VERSION "2027-draft-2026-10-23"

NS_ :

BS_:

BU_: BPS ElconInterface
VAL_TABLE_ EnableDisable 1 "Enabled" 0 "Disabled" ;
VAL_TABLE_ OnOff 1 "On" 0 "Off" ;
VAL_TABLE_ FaultState 1 "Fault" 0 "OK" ;
VAL_TABLE_ WarningState 1 "Warning" 0 "NoWarning" ;
VAL_TABLE_ DeviceStatus 2 "Waiting" 1 "Fault" 0 "OK" ;
VAL_TABLE_ Permission 1 "Allowed" 0 "NotAllowed" ;
VAL_TABLE_ Connection 1 "Connected" 0 "Disconnected" ;
VAL_TABLE_ ServerConnection 1 "Connected" 0 "Disconnected/Retrying" ;
VAL_TABLE_ Pressed 1 "Pressed" 0 "NotPressed" ;
VAL_TABLE_ Validity 1 "Valid" 0 "Invalid" ;
VAL_TABLE_ Watchdog 1 "TimedOut" 0 "Alive" ;
VAL_TABLE_ NormalAdvanced 1 "Advanced" 0 "Normal" ;
VAL_TABLE_ MotorCommandSource 1 "External" 0 "VCU" ;
VAL_TABLE_ Gear 3 "Invalid" 2 "Reverse" 1 "Forward" 0 "Neutral" ;
VAL_TABLE_ BPSFaultSummary 5 "SMBFault" 4 "PrechargeFault" 3 "ContactorRelayFault" 2 "EmergencyStop" 1 "SetpointFault" 0 "OK" ;
VAL_TABLE_ VCUState 7 "VehicleNotReady" 6 "Disabled" 5 "CruiseControl" 4 "Regen" 3 "ReverseDrive" 2 "NeutralDrive" 1 "ForwardDrive" 0 "Init" ;
VAL_TABLE_ ChargeState 2 "Charging" 1 "Standby" 0 "Disabled" ;
VAL_TABLE_ EVSEState 5 "F_EVSEFault" 4 "E_Fault" 3 "D_VentilationRequired" 2 "C_ChargingReady" 1 "B_Connected" 0 "A_Disconnected" ;
VAL_TABLE_ GPSAntennaState 3 "Unknown" 2 "ShortCircuit" 1 "OpenCircuit" 0 "OK" ;
VAL_TABLE_ GPSFix 2 "Fix3D" 1 "Fix2D" 0 "NoFix" ;
VAL_TABLE_ CellularTechnology 4 "Other" 3 "NB_IoT" 2 "LTE_M" 1 "LTE" 0 "None" ;
VAL_TABLE_ TPEEControlMode 2 "ConstantInputVoltage" 1 "PerturbAndObserve" 0 "Disabled" ;
VAL_TABLE_ TPEEOperatingMode 7 "Fault" 6 "MinimumInputVoltage" 5 "TemperatureDerating" 4 "ConstantOutputCurrent" 3 "ConstantOutputVoltage" 2 "MinimumInputCurrent" 1 "ConstantInputCurrent" 0 "ConstantInputVoltage" ;
VAL_TABLE_ TPEEFault 8 "Fault" 7 "PhaseOverCurrent" 6 "InputUnderCurrent" 5 "InputOverCurrent" 4 "OutputOverCurrent" 3 "OutputOverVoltage" 2 "InputOverVoltage" 1 "ConfigurationError" 0 "OK" ;
VAL_TABLE_ LWSCalibration 1 "Calibrated" 0 "NotCalibrated" ;
VAL_TABLE_ LWSTrim 1 "Trimmed" 0 "NotTrimmed" ;
VAL_TABLE_ LWSCommand 5 "ResetCalibration" 3 "SetAngleZero" ;
VAL_TABLE_ ElconControl 1 "Disable" 0 "Charge" ;
VAL_TABLE_ ElconMuxPage 5 "Page5" 4 "Page4" 3 "Page3" 2 "Page2" 1 "Page1" ;

BO_ 96 BPSStatus: 16 BPS
 SG_ Status : 0|2@1+ (1,0) [0.0|3.0] "" Vector__XXX
 SG_ FaultSummary : 2|3@1+ (1,0) [0.0|7.0] "" Vector__XXX
 SG_ FaultOverTemperature : 5|1@1+ (1,0) [0.0|1.0] "" Vector__XXX
 SG_ FaultOverVoltage : 6|1@1+ (1,0) [0.0|1.0] "" Vector__XXX
 SG_ FaultUnderVoltage : 7|1@1+ (1,0) [0.0|1.0] "" Vector__XXX
 SG_ FaultChargeOverCurrent : 8|1@1+ (1,0) [0.0|1.0] "" Vector__XXX
 SG_ FaultDischargeOverCurrent : 9|1@1+ (1,0) [0.0|1.0] "" Vector__XXX
 SG_ FaultHVPositiveContactorMismatch : 10|1@1+ (1,0) [0.0|1.0] "" Vector__XXX
 SG_ FaultMotorContactorMismatch : 11|1@1+ (1,0) [0.0|1.0] "" Vector__XXX
 SG_ FaultHVNegativeContactorMismatch : 12|1@1+ (1,0) [0.0|1.0] "" Vector__XXX
 SG_ FaultMainPrechargeRelayMismatch : 13|1@1+ (1,0) [0.0|1.0] "" Vector__XXX
 SG_ FaultMotorPrechargeRelayMismatch : 14|1@1+ (1,0) [0.0|1.0] "" Vector__XXX
 SG_ FaultDriverEstop : 15|1@1+ (1,0) [0.0|1.0] "" Vector__XXX
 SG_ FaultExternalEstop : 16|1@1+ (1,0) [0.0|1.0] "" Vector__XXX
 SG_ FaultBatteryEstop : 17|1@1+ (1,0) [0.0|1.0] "" Vector__XXX
 SG_ FaultChargerEstop : 18|1@1+ (1,0) [0.0|1.0] "" Vector__XXX
 SG_ FaultMainPrechargeTimeout : 19|1@1+ (1,0) [0.0|1.0] "" Vector__XXX
 SG_ FaultMotorPrechargeTimeout : 20|1@1+ (1,0) [0.0|1.0] "" Vector__XXX
 SG_ FaultMainVoltage : 21|1@1+ (1,0) [0.0|1.0] "" Vector__XXX
 SG_ FaultMotorVoltage : 22|1@1+ (1,0) [0.0|1.0] "" Vector__XXX
 SG_ FaultMainPrechargeVoltage : 23|1@1+ (1,0) [0.0|1.0] "" Vector__XXX
 SG_ FaultMotorPrechargeVoltage : 24|1@1+ (1,0) [0.0|1.0] "" Vector__XXX
 SG_ WarningSMBCommunication : 25|1@1+ (1,0) [0.0|1.0] "" Vector__XXX
 SG_ WarningUnderVoltage : 26|1@1+ (1,0) [0.0|1.0] "" Vector__XXX
 SG_ WarningOverVoltage : 27|1@1+ (1,0) [0.0|1.0] "" Vector__XXX
 SG_ WarningChargeOverTemperature : 28|1@1+ (1,0) [0.0|1.0] "" Vector__XXX
 SG_ WarningDischargeOverTemperature : 29|1@1+ (1,0) [0.0|1.0] "" Vector__XXX
 SG_ WarningBatteryFan1 : 30|1@1+ (1,0) [0.0|1.0] "" Vector__XXX
 SG_ WarningBatteryFan2 : 31|1@1+ (1,0) [0.0|1.0] "" Vector__XXX
 SG_ WarningBPSFan : 32|1@1+ (1,0) [0.0|1.0] "" Vector__XXX
 SG_ DriveOK : 33|1@1+ (1,0) [0.0|1.0] "" Vector__XXX
 SG_ ChargeOK : 34|1@1+ (1,0) [0.0|1.0] "" Vector__XXX
 SG_ MPPTSetMode : 35|2@1+ (1,0) [0.0|3.0] "" Vector__XXX
 SG_ ElconChargeOK : 37|1@1+ (1,0) [0.0|1.0] "" Vector__XXX
 SG_ RegenChargeOK : 38|1@1+ (1,0) [0.0|1.0] "" Vector__XXX
 SG_ HVPositiveContactor : 39|1@1+ (1,0) [0.0|1.0] "" Vector__XXX
 SG_ MotorContactor : 40|1@1+ (1,0) [0.0|1.0] "" Vector__XXX
 SG_ HVNegativeContactor : 41|1@1+ (1,0) [0.0|1.0] "" Vector__XXX
 SG_ MainPrechargeRelay : 42|1@1+ (1,0) [0.0|1.0] "" Vector__XXX
 SG_ MotorPrechargeRelay : 43|1@1+ (1,0) [0.0|1.0] "" Vector__XXX
 SG_ MPPTVoltageLimit : 44|16@1+ (0.05,0) [0|175] "V" Vector__XXX
 SG_ MPPTCurrentLimit : 60|16@1+ (0.01,0) [0|16.38] "A" Vector__XXX
 SG_ BatteryFanTach1 : 76|12@1+ (5,0) [0.0|20475.0] "rpm" Vector__XXX
 SG_ BatteryFanTach2 : 88|12@1+ (5,0) [0.0|20475.0] "rpm" Vector__XXX
 SG_ BPSFanTach : 100|12@1+ (5,0) [0.0|20475.0] "rpm" Vector__XXX
 SG_ SampleAgeMs : 112|16@1+ (1,0) [0|65535] "ms" Vector__XXX

BO_ 112 BPSPackData: 12 BPS
 SG_ CellSumVoltage : 0|12@1+ (0.05,0) [0.0|204.75] "V" Vector__XXX
 SG_ MainBatteryVoltage : 12|12@1+ (0.05,0) [0.0|204.75] "V" Vector__XXX
 SG_ MotorBatteryVoltage : 24|12@1+ (0.05,0) [0.0|204.75] "V" Vector__XXX
 SG_ MainVoltage : 36|12@1+ (0.05,0) [0.0|204.75] "V" Vector__XXX
 SG_ MotorVoltage : 48|12@1+ (0.05,0) [0.0|204.75] "V" Vector__XXX
 SG_ BatteryCurrent : 60|14@1+ (0.01,-50) [-50.0|113.83] "A" Vector__XXX
 SG_ SampleAgeMs : 74|16@1+ (1,0) [0|65535] "ms" Vector__XXX

BO_ 113 BPSVoltageData: 64 BPS
 SG_ CellVoltage01 : 0|12@1+ (1,2000) [2000.0|6095.0] "mV" Vector__XXX
 SG_ CellVoltage02 : 12|12@1+ (1,2000) [2000.0|6095.0] "mV" Vector__XXX
 SG_ CellVoltage03 : 24|12@1+ (1,2000) [2000.0|6095.0] "mV" Vector__XXX
 SG_ CellVoltage04 : 36|12@1+ (1,2000) [2000.0|6095.0] "mV" Vector__XXX
 SG_ CellVoltage05 : 48|12@1+ (1,2000) [2000.0|6095.0] "mV" Vector__XXX
 SG_ CellVoltage06 : 60|12@1+ (1,2000) [2000.0|6095.0] "mV" Vector__XXX
 SG_ CellVoltage07 : 72|12@1+ (1,2000) [2000.0|6095.0] "mV" Vector__XXX
 SG_ CellVoltage08 : 84|12@1+ (1,2000) [2000.0|6095.0] "mV" Vector__XXX
 SG_ CellVoltage09 : 96|12@1+ (1,2000) [2000.0|6095.0] "mV" Vector__XXX
 SG_ CellVoltage10 : 108|12@1+ (1,2000) [2000.0|6095.0] "mV" Vector__XXX
 SG_ CellVoltage11 : 120|12@1+ (1,2000) [2000.0|6095.0] "mV" Vector__XXX
 SG_ CellVoltage12 : 132|12@1+ (1,2000) [2000.0|6095.0] "mV" Vector__XXX
 SG_ CellVoltage13 : 144|12@1+ (1,2000) [2000.0|6095.0] "mV" Vector__XXX
 SG_ CellVoltage14 : 156|12@1+ (1,2000) [2000.0|6095.0] "mV" Vector__XXX
 SG_ CellVoltage15 : 168|12@1+ (1,2000) [2000.0|6095.0] "mV" Vector__XXX
 SG_ CellVoltage16 : 180|12@1+ (1,2000) [2000.0|6095.0] "mV" Vector__XXX
 SG_ CellVoltage17 : 192|12@1+ (1,2000) [2000.0|6095.0] "mV" Vector__XXX
 SG_ CellVoltage18 : 204|12@1+ (1,2000) [2000.0|6095.0] "mV" Vector__XXX
 SG_ CellVoltage19 : 216|12@1+ (1,2000) [2000.0|6095.0] "mV" Vector__XXX
 SG_ CellVoltage20 : 228|12@1+ (1,2000) [2000.0|6095.0] "mV" Vector__XXX
 SG_ CellVoltage21 : 240|12@1+ (1,2000) [2000.0|6095.0] "mV" Vector__XXX
 SG_ CellVoltage22 : 252|12@1+ (1,2000) [2000.0|6095.0] "mV" Vector__XXX
 SG_ CellVoltage23 : 264|12@1+ (1,2000) [2000.0|6095.0] "mV" Vector__XXX
 SG_ CellVoltage24 : 276|12@1+ (1,2000) [2000.0|6095.0] "mV" Vector__XXX
 SG_ CellVoltage25 : 288|12@1+ (1,2000) [2000.0|6095.0] "mV" Vector__XXX
 SG_ CellVoltage26 : 300|12@1+ (1,2000) [2000.0|6095.0] "mV" Vector__XXX
 SG_ CellVoltage27 : 312|12@1+ (1,2000) [2000.0|6095.0] "mV" Vector__XXX
 SG_ CellVoltage28 : 324|12@1+ (1,2000) [2000.0|6095.0] "mV" Vector__XXX
 SG_ CellVoltage29 : 336|12@1+ (1,2000) [2000.0|6095.0] "mV" Vector__XXX
 SG_ CellVoltage30 : 348|12@1+ (1,2000) [2000.0|6095.0] "mV" Vector__XXX
 SG_ CellVoltage31 : 360|12@1+ (1,2000) [2000.0|6095.0] "mV" Vector__XXX
 SG_ CellVoltage32 : 372|12@1+ (1,2000) [2000.0|6095.0] "mV" Vector__XXX
 SG_ MinCellVoltage : 384|12@1+ (1,2000) [2000.0|6095.0] "mV" Vector__XXX
 SG_ MaxCellVoltage : 396|12@1+ (1,2000) [2000.0|6095.0] "mV" Vector__XXX
 SG_ SampleAgeMs : 408|16@1+ (1,0) [0|65535] "ms" Vector__XXX

BO_ 114 BPSTemperatureData: 64 BPS
 SG_ CellTemperature01 : 0|11@1+ (0.05,0) [0.0|102.35] "degC" Vector__XXX
 SG_ CellTemperature02 : 11|11@1+ (0.05,0) [0.0|102.35] "degC" Vector__XXX
 SG_ CellTemperature03 : 22|11@1+ (0.05,0) [0.0|102.35] "degC" Vector__XXX
 SG_ CellTemperature04 : 33|11@1+ (0.05,0) [0.0|102.35] "degC" Vector__XXX
 SG_ CellTemperature05 : 44|11@1+ (0.05,0) [0.0|102.35] "degC" Vector__XXX
 SG_ CellTemperature06 : 55|11@1+ (0.05,0) [0.0|102.35] "degC" Vector__XXX
 SG_ CellTemperature07 : 66|11@1+ (0.05,0) [0.0|102.35] "degC" Vector__XXX
 SG_ CellTemperature08 : 77|11@1+ (0.05,0) [0.0|102.35] "degC" Vector__XXX
 SG_ CellTemperature09 : 88|11@1+ (0.05,0) [0.0|102.35] "degC" Vector__XXX
 SG_ CellTemperature10 : 99|11@1+ (0.05,0) [0.0|102.35] "degC" Vector__XXX
 SG_ CellTemperature11 : 110|11@1+ (0.05,0) [0.0|102.35] "degC" Vector__XXX
 SG_ CellTemperature12 : 121|11@1+ (0.05,0) [0.0|102.35] "degC" Vector__XXX
 SG_ CellTemperature13 : 132|11@1+ (0.05,0) [0.0|102.35] "degC" Vector__XXX
 SG_ CellTemperature14 : 143|11@1+ (0.05,0) [0.0|102.35] "degC" Vector__XXX
 SG_ CellTemperature15 : 154|11@1+ (0.05,0) [0.0|102.35] "degC" Vector__XXX
 SG_ CellTemperature16 : 165|11@1+ (0.05,0) [0.0|102.35] "degC" Vector__XXX
 SG_ CellTemperature17 : 176|11@1+ (0.05,0) [0.0|102.35] "degC" Vector__XXX
 SG_ CellTemperature18 : 187|11@1+ (0.05,0) [0.0|102.35] "degC" Vector__XXX
 SG_ CellTemperature19 : 198|11@1+ (0.05,0) [0.0|102.35] "degC" Vector__XXX
 SG_ CellTemperature20 : 209|11@1+ (0.05,0) [0.0|102.35] "degC" Vector__XXX
 SG_ CellTemperature21 : 220|11@1+ (0.05,0) [0.0|102.35] "degC" Vector__XXX
 SG_ CellTemperature22 : 231|11@1+ (0.05,0) [0.0|102.35] "degC" Vector__XXX
 SG_ CellTemperature23 : 242|11@1+ (0.05,0) [0.0|102.35] "degC" Vector__XXX
 SG_ CellTemperature24 : 253|11@1+ (0.05,0) [0.0|102.35] "degC" Vector__XXX
 SG_ CellTemperature25 : 264|11@1+ (0.05,0) [0.0|102.35] "degC" Vector__XXX
 SG_ CellTemperature26 : 275|11@1+ (0.05,0) [0.0|102.35] "degC" Vector__XXX
 SG_ CellTemperature27 : 286|11@1+ (0.05,0) [0.0|102.35] "degC" Vector__XXX
 SG_ CellTemperature28 : 297|11@1+ (0.05,0) [0.0|102.35] "degC" Vector__XXX
 SG_ CellTemperature29 : 308|11@1+ (0.05,0) [0.0|102.35] "degC" Vector__XXX
 SG_ CellTemperature30 : 319|11@1+ (0.05,0) [0.0|102.35] "degC" Vector__XXX
 SG_ CellTemperature31 : 330|11@1+ (0.05,0) [0.0|102.35] "degC" Vector__XXX
 SG_ CellTemperature32 : 341|11@1+ (0.05,0) [0.0|102.35] "degC" Vector__XXX
 SG_ MaxBatteryTemperature : 352|11@1+ (0.05,0) [0.0|102.35] "degC" Vector__XXX
 SG_ AverageBatteryTemperature : 363|11@1+ (0.05,0) [0.0|102.35] "degC" Vector__XXX
 SG_ SampleAgeMs : 374|16@1+ (1,0) [0|65535] "ms" Vector__XXX

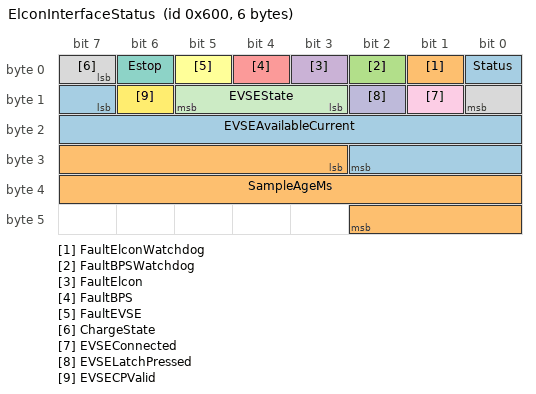
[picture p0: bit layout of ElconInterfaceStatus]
BO_ 1536 ElconInterfaceStatus: 6 ElconInterface
 SG_ Status : 0|1@1+ (1,0) [0.0|1.0] "" Vector__XXX
 SG_ FaultElconWatchdog : 1|1@1+ (1,0) [0.0|1.0] "" Vector__XXX
 SG_ FaultBPSWatchdog : 2|1@1+ (1,0) [0.0|1.0] "" Vector__XXX
 SG_ FaultElcon : 3|1@1+ (1,0) [0.0|1.0] "" Vector__XXX
 SG_ FaultBPS : 4|1@1+ (1,0) [0.0|1.0] "" Vector__XXX
 SG_ FaultEVSE : 5|1@1+ (1,0) [0.0|1.0] "" Vector__XXX
 SG_ Estop : 6|1@1+ (1,0) [0.0|1.0] "" Vector__XXX
 SG_ ChargeState : 7|2@1+ (1,0) [0.0|3.0] "" Vector__XXX
 SG_ EVSEConnected : 9|1@1+ (1,0) [0.0|1.0] "" Vector__XXX
 SG_ EVSELatchPressed : 10|1@1+ (1,0) [0.0|1.0] "" Vector__XXX
 SG_ EVSEState : 11|3@1+ (1,0) [0.0|7.0] "" Vector__XXX
 SG_ EVSECPValid : 14|1@1+ (1,0) [0.0|1.0] "" Vector__XXX
 SG_ EVSEAvailableCurrent : 15|12@1+ (0.01,0) [0|25.5] "A" Vector__XXX
 SG_ SampleAgeMs : 27|16@1+ (1,0) [0|65535] "ms" Vector__XXX

CM_ BO_ 96 "BPS faults, warnings, state, contactors, control permissions, MPPT limits, and fan tachometers. Pack measurements are in BPSPackData (0x070). CAN-FD; no transmit period assigned yet.";
CM_ SG_ 96 SampleAgeMs "Age in milliseconds of the oldest continuous sensor sample included in this frame when assembled; saturates at 65535. Age must advance for cached samples. In a fault snapshot, freeze age at fault detection; per-channel captured ages, if present, remain authoritative for individual trip records.";
CM_ SG_ 96 BPSFanTach "BPSFanTach";
CM_ SG_ 96 BatteryFanTach2 "BatteryFan2Tach";
CM_ SG_ 96 BatteryFanTach1 "BatteryFan1Tach";
CM_ SG_ 96 MPPTCurrentLimit "MPPTCurrentLimit";
CM_ SG_ 96 MPPTVoltageLimit "MPPTVoltageLimit";
CM_ SG_ 96 MotorPrechargeRelay "MotorPrechargeRelay";
CM_ SG_ 96 MainPrechargeRelay "MainPrechargeRelay";
CM_ SG_ 96 HVNegativeContactor "HVNegativeContactor";
CM_ SG_ 96 MotorContactor "MotorContactor";
CM_ SG_ 96 HVPositiveContactor "HVPositiveContactor";
CM_ SG_ 96 RegenChargeOK "RegenChargeOK";
CM_ SG_ 96 ElconChargeOK "ElconChargeOK";
CM_ SG_ 96 MPPTSetMode "MPPTSetMode";
CM_ SG_ 96 ChargeOK "ChargeOK";
CM_ SG_ 96 DriveOK "DriveOK";
CM_ SG_ 96 WarningBPSFan "WarningBPSFan";
CM_ SG_ 96 WarningBatteryFan2 "WarningBatteryFan2";
CM_ SG_ 96 WarningBatteryFan1 "WarningBatteryFan1";
CM_ SG_ 96 WarningDischargeOverTemperature "WarningDischargeOverTemperature";
CM_ SG_ 96 WarningChargeOverTemperature "WarningChargeOverTemperature";
CM_ SG_ 96 WarningOverVoltage "WarningOverVoltage";
CM_ SG_ 96 WarningUnderVoltage "WarningUnderVoltage";
CM_ SG_ 96 WarningSMBCommunication "WarningSMBCommunication";
CM_ SG_ 96 FaultMotorPrechargeVoltage "FaultMotorPrechargeVoltage";
CM_ SG_ 96 FaultMainPrechargeVoltage "FaultMainPrechargeVoltage";
CM_ SG_ 96 FaultMotorVoltage "FaultMotorVoltage";
CM_ SG_ 96 FaultMainVoltage "FaultMainVoltage";
CM_ SG_ 96 FaultMotorPrechargeTimeout "FaultMotorPrechargeTimeout";
CM_ SG_ 96 FaultMainPrechargeTimeout "FaultMainPrechargeTimeout";
CM_ SG_ 96 FaultChargerEstop "FaultChargerEstop";
CM_ SG_ 96 FaultBatteryEstop "FaultBatteryEstop";
CM_ SG_ 96 FaultExternalEstop "FaultExternalEstop";
CM_ SG_ 96 FaultDriverEstop "FaultDriverEstop";
CM_ SG_ 96 FaultMotorPrechargeRelayMismatch "FaultMotorPrechargeRelayMismatch";
CM_ SG_ 96 FaultMainPrechargeRelayMismatch "FaultMainPrechargeRelayMismatch";
CM_ SG_ 96 FaultHVNegativeContactorMismatch "FaultHVNegativeContactorMismatch";
CM_ SG_ 96 FaultMotorContactorMismatch "FaultMotorContactorMismatch";
CM_ SG_ 96 FaultHVPositiveContactorMismatch "FaultHVPositiveContactorMismatch";
CM_ SG_ 96 FaultDischargeOverCurrent "FaultDischargeOverCurrent";
CM_ SG_ 96 FaultChargeOverCurrent "FaultChargeOverCurrent";
CM_ SG_ 96 FaultUnderVoltage "FaultUnderVoltage";
CM_ SG_ 96 FaultOverVoltage "FaultOverVoltage";
CM_ SG_ 96 FaultOverTemperature "FaultOverTemperature";
CM_ SG_ 96 FaultSummary "FaultSummary";
CM_ SG_ 96 Status "Status";
CM_ BO_ 112 "BPS pack electrical measurements: cell-sum and main/motor battery and precharge voltages, then battery current. Cell-voltage extrema are in BPSVoltageData; temperature summaries are in BPSTemperatureData. Signal encodings unchanged; no transmit period assigned yet.";
CM_ SG_ 112 SampleAgeMs "Age in milliseconds of the oldest continuous sensor sample included in this frame when assembled; saturates at 65535. Age must advance for cached samples. In a fault snapshot, freeze age at fault detection; per-channel captured ages, if present, remain authoritative for individual trip records.";
CM_ SG_ 112 BatteryCurrent "BatteryCurrent";
CM_ SG_ 112 MotorVoltage "MotorVoltage";
CM_ SG_ 112 MainVoltage "MainVoltage";
CM_ SG_ 112 MotorBatteryVoltage "MotorBatteryVoltage";
CM_ SG_ 112 MainBatteryVoltage "MainBatteryVoltage";
CM_ SG_ 112 CellSumVoltage "Sum of the 32 cell-tap voltages, independent of precharge measurements. Bulk voltage encoding: unsigned 12 bits, 0.05 V/bit, offset 0 V.";
CM_ BO_ 113 "BPS individual cell voltages followed by minimum/maximum cell voltage; unchanged physical encodings.";
CM_ SG_ 113 SampleAgeMs "Age in milliseconds of the oldest continuous sensor sample included in this frame when assembled; saturates at 65535. Age must advance for cached samples. In a fault snapshot, freeze age at fault detection; per-channel captured ages, if present, remain authoritative for individual trip records.";
CM_ SG_ 113 MaxCellVoltage "MaxCellVoltage";
CM_ SG_ 113 MinCellVoltage "MinCellVoltage";
CM_ SG_ 113 CellVoltage32 "CellVoltage32";
CM_ SG_ 113 CellVoltage31 "CellVoltage31";
CM_ SG_ 113 CellVoltage30 "CellVoltage30";
CM_ SG_ 113 CellVoltage29 "CellVoltage29";
CM_ SG_ 113 CellVoltage28 "CellVoltage28";
CM_ SG_ 113 CellVoltage27 "CellVoltage27";
CM_ SG_ 113 CellVoltage26 "CellVoltage26";
CM_ SG_ 113 CellVoltage25 "CellVoltage25";
CM_ SG_ 113 CellVoltage24 "CellVoltage24";
CM_ SG_ 113 CellVoltage23 "CellVoltage23";
CM_ SG_ 113 CellVoltage22 "CellVoltage22";
CM_ SG_ 113 CellVoltage21 "CellVoltage21";
CM_ SG_ 113 CellVoltage20 "CellVoltage20";
CM_ SG_ 113 CellVoltage19 "CellVoltage19";
CM_ SG_ 113 CellVoltage18 "CellVoltage18";
CM_ SG_ 113 CellVoltage17 "CellVoltage17";
CM_ SG_ 113 CellVoltage16 "CellVoltage16";
CM_ SG_ 113 CellVoltage15 "CellVoltage15";
CM_ SG_ 113 CellVoltage14 "CellVoltage14";
CM_ SG_ 113 CellVoltage13 "CellVoltage13";
CM_ SG_ 113 CellVoltage12 "CellVoltage12";
CM_ SG_ 113 CellVoltage11 "CellVoltage11";
CM_ SG_ 113 CellVoltage10 "CellVoltage10";
CM_ SG_ 113 CellVoltage09 "CellVoltage09";
CM_ SG_ 113 CellVoltage08 "CellVoltage08";
CM_ SG_ 113 CellVoltage07 "CellVoltage07";
CM_ SG_ 113 CellVoltage06 "CellVoltage06";
CM_ SG_ 113 CellVoltage05 "CellVoltage05";
CM_ SG_ 113 CellVoltage04 "CellVoltage04";
CM_ SG_ 113 CellVoltage03 "CellVoltage03";
CM_ SG_ 113 CellVoltage02 "CellVoltage02";
CM_ SG_ 113 CellVoltage01 "CellVoltage01";
CM_ BO_ 114 "BPS individual cell temperatures followed by maximum/average battery temperature; unchanged physical encodings.";
CM_ SG_ 114 SampleAgeMs "Age in milliseconds of the oldest continuous sensor sample included in this frame when assembled; saturates at 65535. Age must advance for cached samples. In a fault snapshot, freeze age at fault detection; per-channel captured ages, if present, remain authoritative for individual trip records.";
CM_ SG_ 114 AverageBatteryTemperature "AverageBatteryTemperature";
CM_ SG_ 114 MaxBatteryTemperature "MaxBatteryTemperature";
CM_ SG_ 114 CellTemperature32 "CellTemperature32";
CM_ SG_ 114 CellTemperature31 "CellTemperature31";
CM_ SG_ 114 CellTemperature30 "CellTemperature30";
CM_ SG_ 114 CellTemperature29 "CellTemperature29";
CM_ SG_ 114 CellTemperature28 "CellTemperature28";
CM_ SG_ 114 CellTemperature27 "CellTemperature27";
CM_ SG_ 114 CellTemperature26 "CellTemperature26";
CM_ SG_ 114 CellTemperature25 "CellTemperature25";
CM_ SG_ 114 CellTemperature24 "CellTemperature24";
CM_ SG_ 114 CellTemperature23 "CellTemperature23";
CM_ SG_ 114 CellTemperature22 "CellTemperature22";
CM_ SG_ 114 CellTemperature21 "CellTemperature21";
CM_ SG_ 114 CellTemperature20 "CellTemperature20";
CM_ SG_ 114 CellTemperature19 "CellTemperature19";
CM_ SG_ 114 CellTemperature18 "CellTemperature18";
CM_ SG_ 114 CellTemperature17 "CellTemperature17";
CM_ SG_ 114 CellTemperature16 "CellTemperature16";
CM_ SG_ 114 CellTemperature15 "CellTemperature15";
CM_ SG_ 114 CellTemperature14 "CellTemperature14";
CM_ SG_ 114 CellTemperature13 "CellTemperature13";
CM_ SG_ 114 CellTemperature12 "CellTemperature12";
CM_ SG_ 114 CellTemperature11 "CellTemperature11";
CM_ SG_ 114 CellTemperature10 "CellTemperature10";
CM_ SG_ 114 CellTemperature09 "CellTemperature09";
CM_ SG_ 114 CellTemperature08 "CellTemperature08";
CM_ SG_ 114 CellTemperature07 "CellTemperature07";
CM_ SG_ 114 CellTemperature06 "CellTemperature06";
CM_ SG_ 114 CellTemperature05 "CellTemperature05";
CM_ SG_ 114 CellTemperature04 "CellTemperature04";
CM_ SG_ 114 CellTemperature03 "CellTemperature03";
CM_ SG_ 114 CellTemperature02 "CellTemperature02";
CM_ SG_ 114 CellTemperature01 "CellTemperature01";
CM_ BO_ 1536 "2027 team-defined layout; physical values use the shared scaling conventions.";
CM_ SG_ 1536 SampleAgeMs "Age in milliseconds of the oldest continuous sensor sample included in this frame when assembled; saturates at 65535. Age must advance for cached samples. In a fault snapshot, freeze age at fault detection; per-channel captured ages, if present, remain authoritative for individual trip records.";
CM_ SG_ 1536 EVSEAvailableCurrent "EVSEAvailableCurrent";
CM_ SG_ 1536 EVSECPValid "EVSECPValid";
CM_ SG_ 1536 EVSEState "EVSEState";
CM_ SG_ 1536 EVSELatchPressed "EVSELatchPressed";
CM_ SG_ 1536 EVSEConnected "EVSEConnected";
CM_ SG_ 1536 ChargeState "ChargeState";
CM_ SG_ 1536 Estop "Estop";
CM_ SG_ 1536 FaultEVSE "FaultEVSE";
CM_ SG_ 1536 FaultBPS "FaultBPS";
CM_ SG_ 1536 FaultElcon "FaultElcon";
CM_ SG_ 1536 FaultBPSWatchdog "FaultBPSWatchdog";
CM_ SG_ 1536 FaultElconWatchdog "FaultElconWatchdog";
CM_ SG_ 1536 Status "Status";
BA_DEF_ SG_  "ValueTable" STRING ;
BA_DEF_ BO_  "LayoutPending" INT 0 1;
BA_DEF_ BO_  "ProtocolSource" STRING ;
BA_DEF_  "BusType" STRING ;
BA_DEF_  "DBName" STRING ;
BA_DEF_ BO_  "VFrameFormat" ENUM  "StandardCAN","ExtendedCAN","reserved","J1939PG","reserved","reserved","reserved","reserved","reserved","reserved","reserved","reserved","reserved","reserved","StandardCAN_FD","ExtendedCAN_FD";
BA_DEF_ BO_  "CANFD_BRS" ENUM  "0","1";
BA_DEF_ BO_  "GenMsgSendType" ENUM  "Cyclic","Triggered","None";
BA_DEF_ BO_  "GenMsgCycleTime" INT 0 65535;
BA_DEF_  "DataBaudrate" INT 1 10000000;
BA_DEF_  "Baudrate" INT 1 10000000;
BA_DEF_DEF_  "ValueTable" "";
BA_DEF_DEF_  "LayoutPending" 0;
BA_DEF_DEF_  "ProtocolSource" "";
BA_DEF_DEF_  "BusType" "CAN";
BA_DEF_DEF_  "DBName" "";
BA_DEF_DEF_  "VFrameFormat" "StandardCAN";
BA_DEF_DEF_  "CANFD_BRS" "0";
BA_DEF_DEF_  "GenMsgSendType" "Cyclic";
BA_DEF_DEF_  "GenMsgCycleTime" 0;
BA_ "BusType" "CAN FD";
BA_ "DBName" "ChargerCAN";
BA_ "Baudrate" 250000;
BA_ "DataBaudrate" 250000;
BA_ "ProtocolSource" BO_ 96 "2027 allocation draft";
BA_ "VFrameFormat" BO_ 96 14;
BA_ "GenMsgCycleTime" BO_ 96 200;
BA_ "ValueTable" SG_ 96 MotorPrechargeRelay "OnOff";
BA_ "ValueTable" SG_ 96 MainPrechargeRelay "OnOff";
BA_ "ValueTable" SG_ 96 HVNegativeContactor "OnOff";
BA_ "ValueTable" SG_ 96 MotorContactor "OnOff";
BA_ "ValueTable" SG_ 96 HVPositiveContactor "OnOff";
BA_ "ValueTable" SG_ 96 RegenChargeOK "Permission";
BA_ "ValueTable" SG_ 96 ElconChargeOK "Permission";
BA_ "ValueTable" SG_ 96 MPPTSetMode "TPEEControlMode";
BA_ "ValueTable" SG_ 96 ChargeOK "Permission";
BA_ "ValueTable" SG_ 96 DriveOK "Permission";
BA_ "ValueTable" SG_ 96 WarningBPSFan "WarningState";
BA_ "ValueTable" SG_ 96 WarningBatteryFan2 "WarningState";
BA_ "ValueTable" SG_ 96 WarningBatteryFan1 "WarningState";
BA_ "ValueTable" SG_ 96 WarningDischargeOverTemperature "WarningState";
BA_ "ValueTable" SG_ 96 WarningChargeOverTemperature "WarningState";
BA_ "ValueTable" SG_ 96 WarningOverVoltage "WarningState";
BA_ "ValueTable" SG_ 96 WarningUnderVoltage "WarningState";
BA_ "ValueTable" SG_ 96 WarningSMBCommunication "WarningState";
BA_ "ValueTable" SG_ 96 FaultMotorPrechargeVoltage "FaultState";
BA_ "ValueTable" SG_ 96 FaultMainPrechargeVoltage "FaultState";
BA_ "ValueTable" SG_ 96 FaultMotorVoltage "FaultState";
BA_ "ValueTable" SG_ 96 FaultMainVoltage "FaultState";
BA_ "ValueTable" SG_ 96 FaultMotorPrechargeTimeout "FaultState";
BA_ "ValueTable" SG_ 96 FaultMainPrechargeTimeout "FaultState";
BA_ "ValueTable" SG_ 96 FaultChargerEstop "FaultState";
BA_ "ValueTable" SG_ 96 FaultBatteryEstop "FaultState";
BA_ "ValueTable" SG_ 96 FaultExternalEstop "FaultState";
BA_ "ValueTable" SG_ 96 FaultDriverEstop "FaultState";
BA_ "ValueTable" SG_ 96 FaultMotorPrechargeRelayMismatch "FaultState";
BA_ "ValueTable" SG_ 96 FaultMainPrechargeRelayMismatch "FaultState";
BA_ "ValueTable" SG_ 96 FaultHVNegativeContactorMismatch "FaultState";
BA_ "ValueTable" SG_ 96 FaultMotorContactorMismatch "FaultState";
BA_ "ValueTable" SG_ 96 FaultHVPositiveContactorMismatch "FaultState";
BA_ "ValueTable" SG_ 96 FaultDischargeOverCurrent "FaultState";
BA_ "ValueTable" SG_ 96 FaultChargeOverCurrent "FaultState";
BA_ "ValueTable" SG_ 96 FaultUnderVoltage "FaultState";
BA_ "ValueTable" SG_ 96 FaultOverVoltage "FaultState";
BA_ "ValueTable" SG_ 96 FaultOverTemperature "FaultState";
BA_ "ValueTable" SG_ 96 FaultSummary "BPSFaultSummary";
BA_ "ValueTable" SG_ 96 Status "DeviceStatus";
BA_ "ProtocolSource" BO_ 112 "2027 allocation draft";
BA_ "VFrameFormat" BO_ 112 14;
BA_ "GenMsgCycleTime" BO_ 112 50;
BA_ "ProtocolSource" BO_ 113 "2027 allocation draft";
BA_ "VFrameFormat" BO_ 113 14;
BA_ "GenMsgCycleTime" BO_ 113 100;
BA_ "ProtocolSource" BO_ 114 "2027 allocation draft";
BA_ "VFrameFormat" BO_ 114 14;
BA_ "GenMsgCycleTime" BO_ 114 200;
BA_ "ProtocolSource" BO_ 1536 "2027 allocation draft";
BA_ "VFrameFormat" BO_ 1536 14;
BA_ "GenMsgCycleTime" BO_ 1536 100;
BA_ "ValueTable" SG_ 1536 EVSECPValid "Validity";
BA_ "ValueTable" SG_ 1536 EVSEState "EVSEState";
BA_ "ValueTable" SG_ 1536 EVSELatchPressed "Pressed";
BA_ "ValueTable" SG_ 1536 EVSEConnected "Connection";
BA_ "ValueTable" SG_ 1536 ChargeState "ChargeState";
BA_ "ValueTable" SG_ 1536 Estop "Pressed";
BA_ "ValueTable" SG_ 1536 FaultEVSE "FaultState";
BA_ "ValueTable" SG_ 1536 FaultBPS "FaultState";
BA_ "ValueTable" SG_ 1536 FaultElcon "FaultState";
BA_ "ValueTable" SG_ 1536 FaultBPSWatchdog "FaultState";
BA_ "ValueTable" SG_ 1536 FaultElconWatchdog "FaultState";
BA_ "ValueTable" SG_ 1536 Status "FaultState";
VAL_ 96 MotorPrechargeRelay 0 "Off" 1 "On" ;
VAL_ 96 MainPrechargeRelay 0 "Off" 1 "On" ;
VAL_ 96 HVNegativeContactor 0 "Off" 1 "On" ;
VAL_ 96 MotorContactor 0 "Off" 1 "On" ;
VAL_ 96 HVPositiveContactor 0 "Off" 1 "On" ;
VAL_ 96 RegenChargeOK 0 "NotAllowed" 1 "Allowed" ;
VAL_ 96 ElconChargeOK 0 "NotAllowed" 1 "Allowed" ;
VAL_ 96 MPPTSetMode 0 "Disabled" 1 "PerturbAndObserve" 2 "ConstantInputVoltage" ;
VAL_ 96 ChargeOK 0 "NotAllowed" 1 "Allowed" ;
VAL_ 96 DriveOK 0 "NotAllowed" 1 "Allowed" ;
VAL_ 96 WarningBPSFan 0 "NoWarning" 1 "Warning" ;
VAL_ 96 WarningBatteryFan2 0 "NoWarning" 1 "Warning" ;
VAL_ 96 WarningBatteryFan1 0 "NoWarning" 1 "Warning" ;
VAL_ 96 WarningDischargeOverTemperature 0 "NoWarning" 1 "Warning" ;
VAL_ 96 WarningChargeOverTemperature 0 "NoWarning" 1 "Warning" ;
VAL_ 96 WarningOverVoltage 0 "NoWarning" 1 "Warning" ;
VAL_ 96 WarningUnderVoltage 0 "NoWarning" 1 "Warning" ;
VAL_ 96 WarningSMBCommunication 0 "NoWarning" 1 "Warning" ;
VAL_ 96 FaultMotorPrechargeVoltage 0 "OK" 1 "Fault" ;
VAL_ 96 FaultMainPrechargeVoltage 0 "OK" 1 "Fault" ;
VAL_ 96 FaultMotorVoltage 0 "OK" 1 "Fault" ;
VAL_ 96 FaultMainVoltage 0 "OK" 1 "Fault" ;
VAL_ 96 FaultMotorPrechargeTimeout 0 "OK" 1 "Fault" ;
VAL_ 96 FaultMainPrechargeTimeout 0 "OK" 1 "Fault" ;
VAL_ 96 FaultChargerEstop 0 "OK" 1 "Fault" ;
VAL_ 96 FaultBatteryEstop 0 "OK" 1 "Fault" ;
VAL_ 96 FaultExternalEstop 0 "OK" 1 "Fault" ;
VAL_ 96 FaultDriverEstop 0 "OK" 1 "Fault" ;
VAL_ 96 FaultMotorPrechargeRelayMismatch 0 "OK" 1 "Fault" ;
VAL_ 96 FaultMainPrechargeRelayMismatch 0 "OK" 1 "Fault" ;
VAL_ 96 FaultHVNegativeContactorMismatch 0 "OK" 1 "Fault" ;
VAL_ 96 FaultMotorContactorMismatch 0 "OK" 1 "Fault" ;
VAL_ 96 FaultHVPositiveContactorMismatch 0 "OK" 1 "Fault" ;
VAL_ 96 FaultDischargeOverCurrent 0 "OK" 1 "Fault" ;
VAL_ 96 FaultChargeOverCurrent 0 "OK" 1 "Fault" ;
VAL_ 96 FaultUnderVoltage 0 "OK" 1 "Fault" ;
VAL_ 96 FaultOverVoltage 0 "OK" 1 "Fault" ;
VAL_ 96 FaultOverTemperature 0 "OK" 1 "Fault" ;
VAL_ 96 FaultSummary 0 "OK" 1 "SetpointFault" 2 "EmergencyStop" 3 "ContactorRelayFault" 4 "PrechargeFault" 5 "SMBFault" ;
VAL_ 96 Status 0 "OK" 1 "Fault" 2 "Waiting" ;
VAL_ 1536 EVSECPValid 0 "Invalid" 1 "Valid" ;
VAL_ 1536 EVSEState 0 "A_Disconnected" 1 "B_Connected" 2 "C_ChargingReady" 3 "D_VentilationRequired" 4 "E_Fault" 5 "F_EVSEFault" ;
VAL_ 1536 EVSELatchPressed 0 "NotPressed" 1 "Pressed" ;
VAL_ 1536 EVSEConnected 0 "Disconnected" 1 "Connected" ;
VAL_ 1536 ChargeState 0 "Disabled" 1 "Standby" 2 "Charging" ;
VAL_ 1536 Estop 0 "NotPressed" 1 "Pressed" ;
VAL_ 1536 FaultEVSE 0 "OK" 1 "Fault" ;
VAL_ 1536 FaultBPS 0 "OK" 1 "Fault" ;
VAL_ 1536 FaultElcon 0 "OK" 1 "Fault" ;
VAL_ 1536 FaultBPSWatchdog 0 "OK" 1 "Fault" ;
VAL_ 1536 FaultElconWatchdog 0 "OK" 1 "Fault" ;
VAL_ 1536 Status 0 "OK" 1 "Fault" ;
